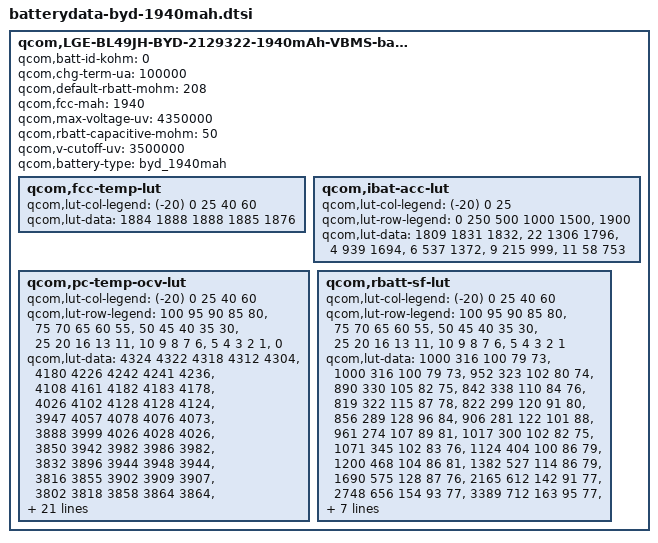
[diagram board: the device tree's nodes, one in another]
/* Copyright (c) 2014, The Linux Foundation. All rights reserved.
 *
 * This program is free software; you can redistribute it and/or modify
 * it under the terms of the GNU General Public License version 2 and
 * only version 2 as published by the Free Software Foundation.
 *
 * This program is distributed in the hope that it will be useful,
 * but WITHOUT ANY WARRANTY; without even the implied warranty of
 * MERCHANTABILITY or FITNESS FOR A PARTICULAR PURPOSE.  See the
 * GNU General Public License for more details.
 */
qcom,LGE-BL49JH-BYD-2129322-1940mAh-VBMS-batterydata {
	qcom,batt-id-kohm = <0>;
	qcom,chg-term-ua = <100000>;
	qcom,default-rbatt-mohm = <208>;
	qcom,fcc-mah = <1940>;
	qcom,max-voltage-uv = <4350000>;
	qcom,rbatt-capacitive-mohm = <50>;
	qcom,v-cutoff-uv = <3500000>;
	qcom,battery-type = "byd_1940mah";

	qcom,fcc-temp-lut {
		qcom,lut-col-legend = <(-20) 0 25 40 60>;
		qcom,lut-data = <1884 1888 1888 1885 1876>;
	};

	qcom,ibat-acc-lut {
		qcom,lut-col-legend = <(-20) 0 25>;
		qcom,lut-row-legend = <0 250 500 1000 1500>,
					<1900>;
		qcom,lut-data = <1809 1831 1832>,
				<22 1306 1796>,
				<4 939 1694>,
				<6 537 1372>,
				<9 215 999>,
				<11 58 753>;
	};

	qcom,pc-temp-ocv-lut {
		qcom,lut-col-legend = <(-20) 0 25 40 60>;
		qcom,lut-row-legend = <100 95 90 85 80>,
					<75 70 65 60 55>,
					<50 45 40 35 30>,
					<25 20 16 13 11>,
					<10 9 8 7 6>,
					<5 4 3 2 1>,
					<0>;
		qcom,lut-data = <4324 4322 4318 4312 4304>,
				<4180 4226 4242 4241 4236>,
				<4108 4161 4182 4183 4178>,
				<4026 4102 4128 4128 4124>,
				<3947 4057 4078 4076 4073>,
				<3888 3999 4026 4028 4026>,
				<3850 3942 3982 3986 3982>,
				<3832 3896 3944 3948 3944>,
				<3816 3855 3902 3909 3907>,
				<3802 3818 3858 3864 3864>,
				<3787 3801 3826 3830 3830>,
				<3772 3793 3804 3808 3807>,
				<3758 3784 3786 3790 3790>,
				<3744 3774 3776 3776 3776>,
				<3730 3764 3769 3764 3758>,
				<3714 3745 3758 3751 3738>,
				<3694 3716 3736 3730 3716>,
				<3673 3697 3707 3702 3691>,
				<3652 3688 3683 3678 3668>,
				<3634 3684 3675 3672 3664>,
				<3623 3680 3672 3670 3662>,
				<3609 3676 3670 3669 3660>,
				<3594 3670 3668 3666 3658>,
				<3576 3662 3665 3664 3654>,
				<3552 3648 3657 3656 3644>,
				<3522 3622 3635 3632 3614>,
				<3484 3583 3590 3585 3566>,
				<3436 3525 3526 3524 3503>,
				<3362 3436 3442 3442 3419>,
				<3236 3306 3326 3317 3297>,
				<3000 3000 3000 3000 3000>;
	};

	qcom,rbatt-sf-lut {
		qcom,lut-col-legend = <(-20) 0 25 40 60>;
		qcom,lut-row-legend = <100 95 90 85 80>,
					<75 70 65 60 55>,
					<50 45 40 35 30>,
					<25 20 16 13 11>,
					<10 9 8 7 6>,
					<5 4 3 2 1>;
		qcom,lut-data = <1000 316 100 79 73>,
				<1000 316 100 79 73>,
				<952 323 102 80 74>,
				<890 330 105 82 75>,
				<842 338 110 84 76>,
				<819 322 115 87 78>,
				<822 299 120 91 80>,
				<856 289 128 96 84>,
				<906 281 122 101 88>,
				<961 274 107 89 81>,
				<1017 300 102 82 75>,
				<1071 345 102 83 76>,
				<1124 404 100 86 79>,
				<1200 468 104 86 81>,
				<1382 527 114 86 79>,
				<1690 575 128 87 76>,
				<2165 612 142 91 77>,
				<2748 656 154 93 77>,
				<3389 712 163 95 77>,
				<4017 764 175 99 80>,
				<4362 792 184 101 82>,
				<4807 821 195 106 83>,
				<5224 836 200 107 84>,
				<5812 854 208 108 85>,
				<6815 897 222 111 84>,
				<8217 950 236 112 84>,
				<10184 1049 252 115 85>,
				<13332 1298 282 124 90>,
				<18535 1775 330 140 101>,
				<32212 2875 415 175 121>;
	};
};
